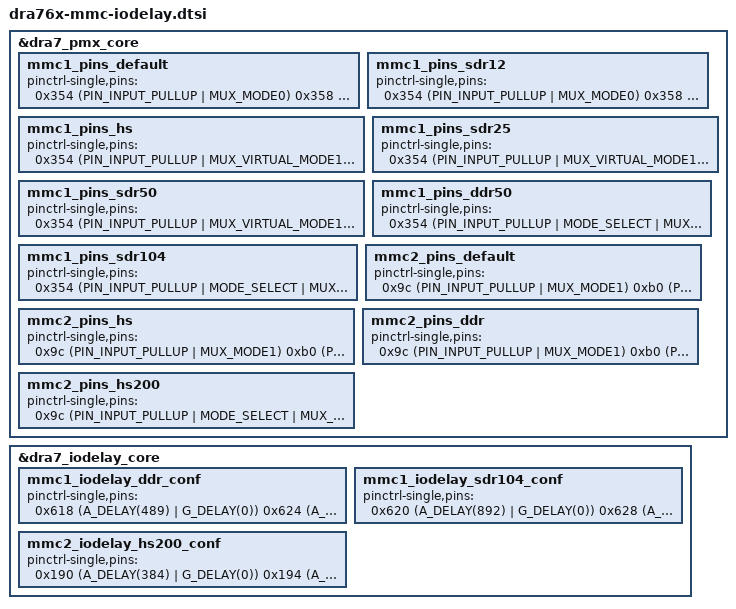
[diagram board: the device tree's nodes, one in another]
/*
 * MMC IOdelay values for TI's DRA76x and AM576x SoCs.
 *
 * Copyright (C) 2017 Texas Instruments Incorporated - http://www.ti.com/
 *
 * This program is free software; you can redistribute it and/or
 * modify it under the terms of the GNU General Public License as
 * published by the Free Software Foundation version 2.
 *
 * This program is distributed "as is" WITHOUT ANY WARRANTY of any
 * kind, whether express or implied; without even the implied warranty
 * of MERCHANTABILITY or FITNESS FOR A PARTICULAR PURPOSE.  See the
 * GNU General Public License for more details.
 */

/*
 * Rules for modifying this file:
 * a) Update of this file should typically correspond to a datamanual revision.
 *    Datamanual revision that was used should be updated in comment below.
 *    If there is no update to datamanual, do not update the values. If you
 *    need to use values different from that recommended by the datamanual
 *    for your design, then you should consider adding values to the device-
 *    -tree file for your board directly.
 * b) We keep the mode names as close to the datamanual as possible. So
 *    if the manual calls a mode, DDR50, or DDR or DDR 1.8v or DDR 3.3v,
 *    we follow that in code too.
 * c) If the values change between multiple revisions of silicon, we add
 *    a revision tag to both the new and old entry. Use 'rev11' for PG 1.1,
 *    'rev20' for PG 2.0 and so on.
 * d) The node name and node label should be the exact same string. This is
 *    to curb naming creativity and achieve consistency.
 *
 * Datamanual Revisions:
 *
 * DRA76x Silicon Revision 1.0: SPRS993A, Revised July 2017
 *
 */

&dra7_pmx_core {
	mmc1_pins_default: mmc1_pins_default {
		pinctrl-single,pins = <
			0x354 (PIN_INPUT_PULLUP | MUX_MODE0)	/* mmc1_clk.clk */
			0x358 (PIN_INPUT_PULLUP | MUX_MODE0)	/* mmc1_cmd.cmd */
			0x35c (PIN_INPUT_PULLUP | MUX_MODE0)	/* mmc1_dat0.dat0 */
			0x360 (PIN_INPUT_PULLUP | MUX_MODE0)	/* mmc1_dat1.dat1 */
			0x364 (PIN_INPUT_PULLUP | MUX_MODE0)	/* mmc1_dat2.dat2 */
			0x368 (PIN_INPUT_PULLUP | MUX_MODE0)	/* mmc1_dat3.dat3 */
		>;
	};

	mmc1_pins_sdr12: mmc1_pins_sdr12 {
		pinctrl-single,pins = <
			0x354 (PIN_INPUT_PULLUP | MUX_MODE0)	/* mmc1_clk.clk */
			0x358 (PIN_INPUT_PULLUP | MUX_MODE0)	/* mmc1_cmd.cmd */
			0x35c (PIN_INPUT_PULLUP | MUX_MODE0)	/* mmc1_dat0.dat0 */
			0x360 (PIN_INPUT_PULLUP | MUX_MODE0)	/* mmc1_dat1.dat1 */
			0x364 (PIN_INPUT_PULLUP | MUX_MODE0)	/* mmc1_dat2.dat2 */
			0x368 (PIN_INPUT_PULLUP | MUX_MODE0)	/* mmc1_dat3.dat3 */
		>;
	};

	mmc1_pins_hs: mmc1_pins_hs {
		pinctrl-single,pins = <
			0x354 (PIN_INPUT_PULLUP | MUX_VIRTUAL_MODE11 | MUX_MODE0) /* mmc1_clk.clk */
			0x358 (PIN_INPUT_PULLUP | MUX_VIRTUAL_MODE11 | MUX_MODE0) /* mmc1_cmd.cmd */
			0x35c (PIN_INPUT_PULLUP | MUX_VIRTUAL_MODE11 | MUX_MODE0) /* mmc1_dat0.dat0 */
			0x360 (PIN_INPUT_PULLUP | MUX_VIRTUAL_MODE11 | MUX_MODE0) /* mmc1_dat1.dat1 */
			0x364 (PIN_INPUT_PULLUP | MUX_VIRTUAL_MODE11 | MUX_MODE0) /* mmc1_dat2.dat2 */
			0x368 (PIN_INPUT_PULLUP | MUX_VIRTUAL_MODE11 | MUX_MODE0) /* mmc1_dat3.dat3 */
		>;
	};

	mmc1_pins_sdr25: mmc1_pins_sdr25 {
		pinctrl-single,pins = <
			0x354 (PIN_INPUT_PULLUP | MUX_VIRTUAL_MODE11 | MUX_MODE0)	/* mmc1_clk.clk */
			0x358 (PIN_INPUT_PULLUP | MUX_VIRTUAL_MODE11 | MUX_MODE0)	/* mmc1_cmd.cmd */
			0x35c (PIN_INPUT_PULLUP | MUX_VIRTUAL_MODE11 | MUX_MODE0)	/* mmc1_dat0.dat0 */
			0x360 (PIN_INPUT_PULLUP | MUX_VIRTUAL_MODE11 | MUX_MODE0)	/* mmc1_dat1.dat1 */
			0x364 (PIN_INPUT_PULLUP | MUX_VIRTUAL_MODE11 | MUX_MODE0)	/* mmc1_dat2.dat2 */
			0x368 (PIN_INPUT_PULLUP | MUX_VIRTUAL_MODE11 | MUX_MODE0)	/* mmc1_dat3.dat3 */
		>;
	};

	mmc1_pins_sdr50: mmc1_pins_sdr50 {
		pinctrl-single,pins = <
			0x354 (PIN_INPUT_PULLUP | MUX_VIRTUAL_MODE10 | MUX_MODE0)	/* mmc1_clk.clk */
			0x358 (PIN_INPUT_PULLUP | MUX_VIRTUAL_MODE10 | MUX_MODE0)	/* mmc1_cmd.cmd */
			0x35c (PIN_INPUT_PULLUP | MUX_VIRTUAL_MODE10 | MUX_MODE0)	/* mmc1_dat0.dat0 */
			0x360 (PIN_INPUT_PULLUP | MUX_VIRTUAL_MODE10 | MUX_MODE0)	/* mmc1_dat1.dat1 */
			0x364 (PIN_INPUT_PULLUP | MUX_VIRTUAL_MODE10 | MUX_MODE0)	/* mmc1_dat2.dat2 */
			0x368 (PIN_INPUT_PULLUP | MUX_VIRTUAL_MODE10 | MUX_MODE0)	/* mmc1_dat3.dat3 */
		>;
	};

	mmc1_pins_ddr50: mmc1_pins_ddr50 {
		pinctrl-single,pins = <
			0x354 (PIN_INPUT_PULLUP | MODE_SELECT | MUX_MODE0)	/* mmc1_clk.clk */
			0x358 (PIN_INPUT_PULLUP | MODE_SELECT | MUX_MODE0)	/* mmc1_cmd.cmd */
			0x35c (PIN_INPUT_PULLUP | MODE_SELECT | MUX_MODE0)	/* mmc1_dat0.dat0 */
			0x360 (PIN_INPUT_PULLUP | MODE_SELECT | MUX_MODE0)	/* mmc1_dat1.dat1 */
			0x364 (PIN_INPUT_PULLUP | MODE_SELECT | MUX_MODE0)	/* mmc1_dat2.dat2 */
			0x368 (PIN_INPUT_PULLUP | MODE_SELECT | MUX_MODE0)	/* mmc1_dat3.dat3 */
		>;
	};

	mmc1_pins_sdr104: mmc1_pins_sdr104 {
		pinctrl-single,pins = <
			0x354 (PIN_INPUT_PULLUP | MODE_SELECT | MUX_MODE0)	/* mmc1_clk.clk */
			0x358 (PIN_INPUT_PULLUP | MODE_SELECT | MUX_MODE0)	/* mmc1_cmd.cmd */
			0x35c (PIN_INPUT_PULLUP | MODE_SELECT | MUX_MODE0)	/* mmc1_dat0.dat0 */
			0x360 (PIN_INPUT_PULLUP | MODE_SELECT | MUX_MODE0)	/* mmc1_dat1.dat1 */
			0x364 (PIN_INPUT_PULLUP | MODE_SELECT | MUX_MODE0)	/* mmc1_dat2.dat2 */
			0x368 (PIN_INPUT_PULLUP | MODE_SELECT | MUX_MODE0)	/* mmc1_dat3.dat3 */
		>;
	};

	mmc2_pins_default: mmc2_pins_default {
		pinctrl-single,pins = <
			0x9c (PIN_INPUT_PULLUP | MUX_MODE1) /* gpmc_a23.mmc2_clk */
			0xb0 (PIN_INPUT_PULLUP | MUX_MODE1) /* gpmc_cs1.mmc2_cmd */
			0xa0 (PIN_INPUT_PULLUP | MUX_MODE1) /* gpmc_a24.mmc2_dat0 */
			0xa4 (PIN_INPUT_PULLUP | MUX_MODE1) /* gpmc_a25.mmc2_dat1 */
			0xa8 (PIN_INPUT_PULLUP | MUX_MODE1) /* gpmc_a26.mmc2_dat2 */
			0xac (PIN_INPUT_PULLUP | MUX_MODE1) /* gpmc_a27.mmc2_dat3 */
			0x8c (PIN_INPUT_PULLUP | MUX_MODE1) /* gpmc_a19.mmc2_dat4 */
			0x90 (PIN_INPUT_PULLUP | MUX_MODE1) /* gpmc_a20.mmc2_dat5 */
			0x94 (PIN_INPUT_PULLUP | MUX_MODE1) /* gpmc_a21.mmc2_dat6 */
			0x98 (PIN_INPUT_PULLUP | MUX_MODE1) /* gpmc_a22.mmc2_dat7 */
		>;
	};

	mmc2_pins_hs: mmc2_pins_hs {
		pinctrl-single,pins = <
			0x9c (PIN_INPUT_PULLUP | MUX_MODE1) /* gpmc_a23.mmc2_clk */
			0xb0 (PIN_INPUT_PULLUP | MUX_MODE1) /* gpmc_cs1.mmc2_cmd */
			0xa0 (PIN_INPUT_PULLUP | MUX_MODE1) /* gpmc_a24.mmc2_dat0 */
			0xa4 (PIN_INPUT_PULLUP | MUX_MODE1) /* gpmc_a25.mmc2_dat1 */
			0xa8 (PIN_INPUT_PULLUP | MUX_MODE1) /* gpmc_a26.mmc2_dat2 */
			0xac (PIN_INPUT_PULLUP | MUX_MODE1) /* gpmc_a27.mmc2_dat3 */
			0x8c (PIN_INPUT_PULLUP | MUX_MODE1) /* gpmc_a19.mmc2_dat4 */
			0x90 (PIN_INPUT_PULLUP | MUX_MODE1) /* gpmc_a20.mmc2_dat5 */
			0x94 (PIN_INPUT_PULLUP | MUX_MODE1) /* gpmc_a21.mmc2_dat6 */
			0x98 (PIN_INPUT_PULLUP | MUX_MODE1) /* gpmc_a22.mmc2_dat7 */
		>;
	};

	mmc2_pins_ddr: mmc2_pins_ddr {
		pinctrl-single,pins = <
			0x9c (PIN_INPUT_PULLUP | MUX_MODE1) /* gpmc_a23.mmc2_clk */
			0xb0 (PIN_INPUT_PULLUP | MUX_MODE1) /* gpmc_cs1.mmc2_cmd */
			0xa0 (PIN_INPUT_PULLUP | MUX_MODE1) /* gpmc_a24.mmc2_dat0 */
			0xa4 (PIN_INPUT_PULLUP | MUX_MODE1) /* gpmc_a25.mmc2_dat1 */
			0xa8 (PIN_INPUT_PULLUP | MUX_MODE1) /* gpmc_a26.mmc2_dat2 */
			0xac (PIN_INPUT_PULLUP | MUX_MODE1) /* gpmc_a27.mmc2_dat3 */
			0x8c (PIN_INPUT_PULLUP | MUX_MODE1) /* gpmc_a19.mmc2_dat4 */
			0x90 (PIN_INPUT_PULLUP | MUX_MODE1) /* gpmc_a20.mmc2_dat5 */
			0x94 (PIN_INPUT_PULLUP | MUX_MODE1) /* gpmc_a21.mmc2_dat6 */
			0x98 (PIN_INPUT_PULLUP | MUX_MODE1) /* gpmc_a22.mmc2_dat7 */
		>;
	};

	mmc2_pins_hs200: mmc2_pins_hs200 {
		pinctrl-single,pins = <
			0x9c (PIN_INPUT_PULLUP | MODE_SELECT | MUX_MODE1) /* gpmc_a23.mmc2_clk */
			0xb0 (PIN_INPUT_PULLUP | MODE_SELECT | MUX_MODE1) /* gpmc_cs1.mmc2_cmd */
			0xa0 (PIN_INPUT_PULLUP | MODE_SELECT | MUX_MODE1) /* gpmc_a24.mmc2_dat0 */
			0xa4 (PIN_INPUT_PULLUP | MODE_SELECT | MUX_MODE1) /* gpmc_a25.mmc2_dat1 */
			0xa8 (PIN_INPUT_PULLUP | MODE_SELECT | MUX_MODE1) /* gpmc_a26.mmc2_dat2 */
			0xac (PIN_INPUT_PULLUP | MODE_SELECT | MUX_MODE1) /* gpmc_a27.mmc2_dat3 */
			0x8c (PIN_INPUT_PULLUP | MODE_SELECT | MUX_MODE1) /* gpmc_a19.mmc2_dat4 */
			0x90 (PIN_INPUT_PULLUP | MODE_SELECT | MUX_MODE1) /* gpmc_a20.mmc2_dat5 */
			0x94 (PIN_INPUT_PULLUP | MODE_SELECT | MUX_MODE1) /* gpmc_a21.mmc2_dat6 */
			0x98 (PIN_INPUT_PULLUP | MODE_SELECT | MUX_MODE1) /* gpmc_a22.mmc2_dat7 */
		>;
	};
};

&dra7_iodelay_core {

	/* Corresponds to MMC1_DDR_MANUAL1 in datamanual */
	mmc1_iodelay_ddr_conf: mmc1_iodelay_ddr_conf {
		pinctrl-single,pins = <
			0x618 (A_DELAY(489) | G_DELAY(0))	/* CFG_MMC1_CLK_IN */
			0x624 (A_DELAY(0) | G_DELAY(0))	/* CFG_MMC1_CMD_IN */
			0x630 (A_DELAY(374) | G_DELAY(0))	/* CFG_MMC1_DAT0_IN */
			0x63c (A_DELAY(31) | G_DELAY(0))	/* CFG_MMC1_DAT1_IN */
			0x648 (A_DELAY(56) | G_DELAY(0))	/* CFG_MMC1_DAT2_IN */
			0x654 (A_DELAY(0) | G_DELAY(0))	/* CFG_MMC1_DAT3_IN */
			0x620 (A_DELAY(1355) | G_DELAY(0))	/* CFG_MMC1_CLK_OUT */
			0x628 (A_DELAY(0) | G_DELAY(0))	/* CFG_MMC1_CMD_OEN */
			0x62c (A_DELAY(0) | G_DELAY(0))	/* CFG_MMC1_CMD_OUT */
			0x634 (A_DELAY(0) | G_DELAY(0))	/* CFG_MMC1_DAT0_OEN */
			0x638 (A_DELAY(0) | G_DELAY(4))	/* CFG_MMC1_DAT0_OUT */
			0x640 (A_DELAY(0) | G_DELAY(0))	/* CFG_MMC1_DAT1_OEN */
			0x644 (A_DELAY(0) | G_DELAY(0))	/* CFG_MMC1_DAT1_OUT */
			0x64c (A_DELAY(0) | G_DELAY(0))	/* CFG_MMC1_DAT2_OEN */
			0x650 (A_DELAY(0) | G_DELAY(0))	/* CFG_MMC1_DAT2_OUT */
			0x658 (A_DELAY(0) | G_DELAY(0))	/* CFG_MMC1_DAT3_OEN */
			0x65c (A_DELAY(0) | G_DELAY(0))	/* CFG_MMC1_DAT3_OUT */
		>;
	};

	/* Corresponds to MMC1_SDR104_MANUAL1 in datamanual */
	mmc1_iodelay_sdr104_conf: mmc1_iodelay_sdr104_conf {
		pinctrl-single,pins = <
			0x620 (A_DELAY(892) | G_DELAY(0))	/* CFG_MMC1_CLK_OUT */
			0x628 (A_DELAY(0) | G_DELAY(0))	/* CFG_MMC1_CMD_OEN */
			0x62c (A_DELAY(0) | G_DELAY(0))	/* CFG_MMC1_CMD_OUT */
			0x634 (A_DELAY(0) | G_DELAY(0))	/* CFG_MMC1_DAT0_OEN */
			0x638 (A_DELAY(0) | G_DELAY(0))	/* CFG_MMC1_DAT0_OUT */
			0x640 (A_DELAY(0) | G_DELAY(0))	/* CFG_MMC1_DAT1_OEN */
			0x644 (A_DELAY(0) | G_DELAY(0))	/* CFG_MMC1_DAT1_OUT */
			0x64c (A_DELAY(0) | G_DELAY(0))	/* CFG_MMC1_DAT2_OEN */
			0x650 (A_DELAY(0) | G_DELAY(0))	/* CFG_MMC1_DAT2_OUT */
			0x658 (A_DELAY(0) | G_DELAY(0))	/* CFG_MMC1_DAT3_OEN */
			0x65c (A_DELAY(0) | G_DELAY(0))	/* CFG_MMC1_DAT3_OUT */
		>;
	};

	/* Corresponds to MMC2_HS200_MANUAL1 in datamanual */
	mmc2_iodelay_hs200_conf: mmc2_iodelay_hs200_conf {
		pinctrl-single,pins = <
			0x190 (A_DELAY(384) | G_DELAY(0))       /* CFG_GPMC_A19_OEN */
			0x194 (A_DELAY(0) | G_DELAY(174))       /* CFG_GPMC_A19_OUT */
			0x1a8 (A_DELAY(410) | G_DELAY(0))       /* CFG_GPMC_A20_OEN */
			0x1ac (A_DELAY(85) | G_DELAY(0))        /* CFG_GPMC_A20_OUT */
			0x1b4 (A_DELAY(468) | G_DELAY(0))       /* CFG_GPMC_A21_OEN */
			0x1b8 (A_DELAY(139) | G_DELAY(0))       /* CFG_GPMC_A21_OUT */
			0x1c0 (A_DELAY(676) | G_DELAY(0))       /* CFG_GPMC_A22_OEN */
			0x1c4 (A_DELAY(69) | G_DELAY(0))        /* CFG_GPMC_A22_OUT */
			0x1d0 (A_DELAY(1062) | G_DELAY(154))	/* CFG_GPMC_A23_OUT */
			0x1d8 (A_DELAY(640) | G_DELAY(0))       /* CFG_GPMC_A24_OEN */
			0x1dc (A_DELAY(0) | G_DELAY(0))         /* CFG_GPMC_A24_OUT */
			0x1e4 (A_DELAY(356) | G_DELAY(0))       /* CFG_GPMC_A25_OEN */
			0x1e8 (A_DELAY(0) | G_DELAY(0))         /* CFG_GPMC_A25_OUT */
			0x1f0 (A_DELAY(579) | G_DELAY(0))       /* CFG_GPMC_A26_OEN */
			0x1f4 (A_DELAY(0) | G_DELAY(0))         /* CFG_GPMC_A26_OUT */
			0x1fc (A_DELAY(435) | G_DELAY(0))       /* CFG_GPMC_A27_OEN */
			0x200 (A_DELAY(36) | G_DELAY(0))        /* CFG_GPMC_A27_OUT */
			0x364 (A_DELAY(759) | G_DELAY(0))       /* CFG_GPMC_CS1_OEN */
			0x368 (A_DELAY(72) | G_DELAY(0))        /* CFG_GPMC_CS1_OUT */
	      >;
	};
};
